AUTOSAR XML (schema 00050)
package /SSM_Slave_1_0/ComponentTypes
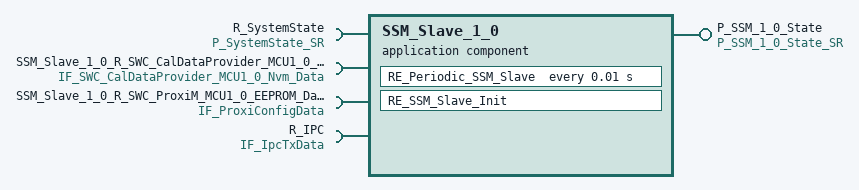
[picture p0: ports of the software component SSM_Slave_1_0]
  application sw component type SSM_Slave_1_0
    provide port P_SSM_1_0_State: nonqueued-sender-com-spec{data-element=State_1_0, init-value=fields=[CoreStatus:0, LocalAppStatus:20 x 0]}, provided-interface=P_SSM_1_0_State_SR
    4 x require port:
      R_SystemState: nonqueued-receiver-com-spec{data-element=SystemState, init-value=fields=[SystemState:0, DegradedState:0]}, required-interface=P_SystemState_SR
      SSM_Slave_1_0_R_SWC_CalDataProvider_MCU1_0_Nvm_Data: nonqueued-receiver-com-spec{data-element=CalData_mcu1_0, filter=data-filter-type=ALWAYS}, required-interface=IF_SWC_CalDataProvider_MCU1_0_Nvm_Data
      SSM_Slave_1_0_R_SWC_ProxiM_MCU1_0_EEPROM_Data: nonqueued-receiver-com-spec{data-element=ProxiData, filter=data-filter-type=ALWAYS, init-value=fields=[bValid:0, ConfigCode:11 x 0, TesterCode:10 x 0, ProductionDate:[0, 0, 0, 0], CanNode14trscm_uint8:0, Variant_ID:0, CanNode27Asm_uint8:0, CanNode63ttm_uint8:0, CanNode67dtcm_uint8:0, CanNode95itcm_uint8:0, StopandStart:0, DriverSide:0, Tyresize_uint16:0, Wheelbase:0, Rearviewcamera:0, Parkwithstop:0, SteeringRatio_uint8:0, Gearboxtype:0, Drivetypevariant:0, Pamtuningset:0, Semiautopark:0, VehicleLineConfiguration_uint8:0, CountryCode_uint8:0, Srt:0, PAMConfig_uint8:0, ModelYear_uint8:0, Hybridtype:0, Pulloutcontrol:0, Surroundviewcamera:0, Forwardfacingcamera:0, Autonomylevel:0, Fullautomaticparking:0, Radiodisplay:0, Mirrortype:0, Auxiliarycamera:0, Trailerreverseguide:0, Trailersurround:0, Trailerreversesteering:0, Trailerhitchassist:0, CVPAM_Presence_uint8:0, SideDistanceWarning:0, PROXIWriteCounter:0]}, required-interface=IF_ProxiConfigData
      R_IPC: client-com-spec=IPC_Write_v, required-interface=IF_IpcTxData
    behavior SSM_Slave_1_0_InternalBehavior: handle-termination-and-restart=NO-SUPPORT
      timing event TMT_RE_Periodic_SSM_Slave: start-on-event=RE_Periodic_SSM_Slave, period=0.01
      init event InitEvent: start-on-event=RE_SSM_Slave_Init
      port-api-options:
        enable-take-address=false, error-handling=NO-TRANSFORMER-ERROR-HANDLING, indirect-api=false, port=P_SSM_1_0_State
        enable-take-address=false, error-handling=NO-TRANSFORMER-ERROR-HANDLING, indirect-api=false, port=R_SystemState
      runnable RE_Periodic_SSM_Slave  # Periodic Runnable of Satellite
        data-receive-point-by-arguments:
          access REC_R_SystemState_SystemState: accessed-variable=R_SystemState.SystemState
          access REC_SSM_Slave_1_0_R_SWC_CalDataProvider_MCU1_0_Nvm_Data_CalData_mcu1_0: accessed-variable=SSM_Slave_1_0_R_SWC_CalDataProvider_MCU1_0_Nvm_Data.CalData_mcu1_0
          access REC_SSM_Slave_1_0_R_SWC_ProxiM_MCU1_0_EEPROM_Data_ProxiData: accessed-variable=SSM_Slave_1_0_R_SWC_ProxiM_MCU1_0_EEPROM_Data.ProxiData
        data-send-points:
          access SEND_P_SSM_1_0_State_State_1_0: accessed-variable=P_SSM_1_0_State.State_1_0
        sync call SC_R_IPC_IPC_Write_v: operation=R_IPC.IPC_Write_v
      runnable RE_SSM_Slave_Init
  swc implementation SSM_Slave_1_0_Implementation: programming-language=C, vendor-id=0, behavior=SSM_Slave_1_0_InternalBehavior
    code-descriptors:
      code Default: artifact-descriptors=autosar-engineering-object=category=SWSRC
